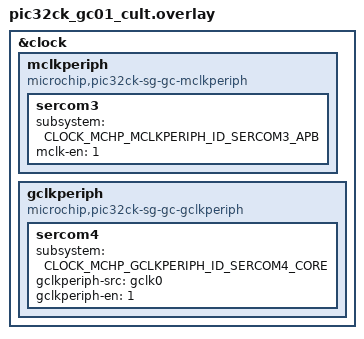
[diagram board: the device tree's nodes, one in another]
/*
 * Copyright (c) 2026 Microchip Technology Inc.
 *
 * SPDX-License-Identifier: Apache-2.0
 */

&clock {
	mclkperiph: mclkperiph {
		compatible = "microchip,pic32ck-sg-gc-mclkperiph";
		#clock-cells = <1>;

		sercom3 {
			subsystem = <CLOCK_MCHP_MCLKPERIPH_ID_SERCOM3_APB>;
			mclk-en = <1>;
		};
	};

	gclkperiph: gclkperiph {
		compatible = "microchip,pic32ck-sg-gc-gclkperiph";
		#clock-cells = <1>;

		sercom4 {
			subsystem = <CLOCK_MCHP_GCLKPERIPH_ID_SERCOM4_CORE>;
			gclkperiph-src = "gclk0";
			gclkperiph-en = <1>;
		};
	};
};
